# CLK1_2_MMU1_BW_LIMITER register map
Vendor: Texas Instruments
Peripheral module from a debugger description file (folder DRA74xP_75xP_76xP_77xP).
Registers are 32-bit, access per field, reset 0x0 unless marked. A register's access mark holds for its fields unless they carry their own. Offsets are as the file gives them; lines under a group give offsets from that group; [hi:lo] are bit positions; {n}, {i} and the like mark numbered series; 'fields as' and 'values as' point back to an identical list; <NAME> marks a mode.

## CLK1_2_MMU1_BW_LIMITER
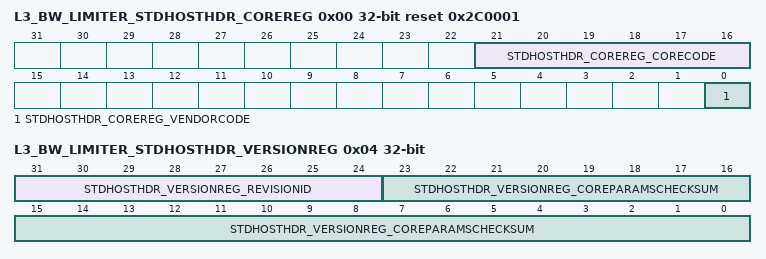
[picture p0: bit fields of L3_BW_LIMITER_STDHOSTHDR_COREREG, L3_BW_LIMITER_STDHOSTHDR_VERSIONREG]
0x00 L3_BW_LIMITER_STDHOSTHDR_COREREG ro reset 0x2C0001
  [21:16] STDHOSTHDR_COREREG_CORECODE — The Core Code field is a constantreporting a vendor-specific core generator code. Type: Constant. Reset value: 0x2C.
  [0] STDHOSTHDR_COREREG_VENDORCODE — The Vendor Code field is a constantreporting the core generator vendor code. Type: Constant. Reset value: 0x1.
    1=ARTERIS; 0=UNDEFINED (Third-party vendor.)
0x04 L3_BW_LIMITER_STDHOSTHDR_VERSIONREG ro
  [31:24] STDHOSTHDR_VERSIONREG_REVISIONID — The Revision Identifier field is a constantreporting the core generator revision number. Type: Constant. Reset value: 0x0.
  [23:0] STDHOSTHDR_VERSIONREG_COREPARAMSCHECKSUM — Reserved. Type: Reserved. Reset value: Reserved.
0x08 L3_BW_LIMITER_BANDWIDTH_FRACTIONAL
  [4:0] BANDWIDTH_FRACTIONAL rw — Fractional part of bandwitdh in terms of bytes per second Type: Control. Reset value: 0x0.
0x0C L3_BW_LIMITER_BANDWIDTH_INTEGER
  [3:0] BANDWIDTH_INTEGER rw — Integer part of bandwitdh in terms of bytes per second Type: Control. Reset value: 0x0.
0x10 L3_BW_LIMITER_WATERMARK_0 reset 0x3FFF
  [13:0] WATERMARK_0 rw — Peak bandwidth allowed Type: Control. Reset value: 0x3FF.
0x14 L3_BW_LIMITER_CLEARHISTORY
  [0] CLEARHISTORY rw — Write a 1 clear the traffic counter Type: Give_AutoCleared. Reset value: 0x0.
